# MOTOR register map
Registers are 32-bit, access not given, no defined reset value unless marked. A register's access mark holds for its fields unless they carry their own. Addresses are absolute; registers are grouped by the start of their names; [hi:lo] are bit positions; {n}, {i} and the like mark numbered series.

## GLOBAL
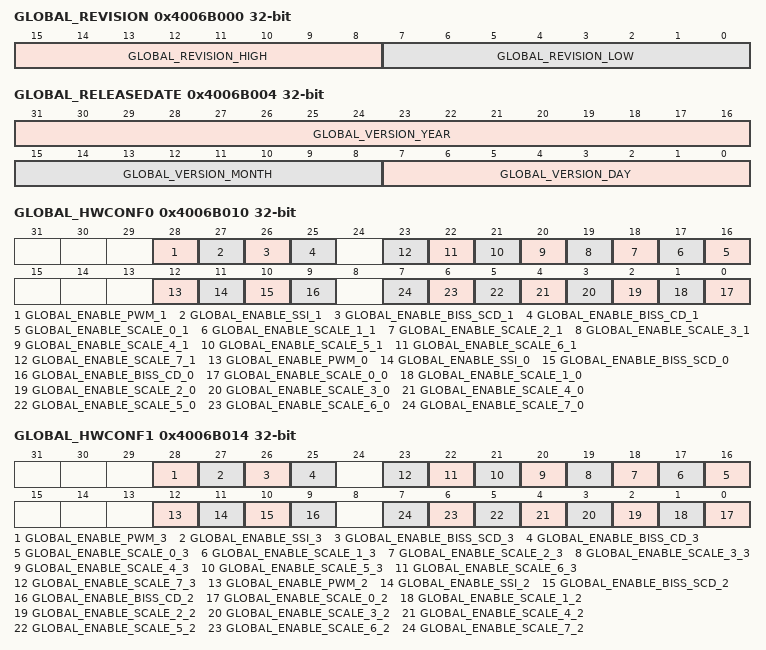
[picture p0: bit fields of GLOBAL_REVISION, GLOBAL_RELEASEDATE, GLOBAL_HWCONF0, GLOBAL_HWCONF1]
0x4006B000 GLOBAL_REVISION ro
  [15:8] GLOBAL_REVISION_HIGH, [7:0] GLOBAL_REVISION_LOW
0x4006B004 GLOBAL_RELEASEDATE ro
  [31:16] GLOBAL_VERSION_YEAR, [15:8] GLOBAL_VERSION_MONTH, [7:0] GLOBAL_VERSION_DAY
0x4006B010 GLOBAL_HWCONF0 ro
  [28] GLOBAL_ENABLE_PWM_1, [27] GLOBAL_ENABLE_SSI_1, [26] GLOBAL_ENABLE_BISS_SCD_1, [25] GLOBAL_ENABLE_BISS_CD_1, [n+16] GLOBAL_ENABLE_SCALE_{n}_1 (n=0..7), [12] GLOBAL_ENABLE_PWM_0, [11] GLOBAL_ENABLE_SSI_0, [10] GLOBAL_ENABLE_BISS_SCD_0, [9] GLOBAL_ENABLE_BISS_CD_0, [n] GLOBAL_ENABLE_SCALE_{n}_0 (n=0..7)
0x4006B014 GLOBAL_HWCONF1 ro
  [28] GLOBAL_ENABLE_PWM_3, [27] GLOBAL_ENABLE_SSI_3, [26] GLOBAL_ENABLE_BISS_SCD_3, [25] GLOBAL_ENABLE_BISS_CD_3, [n+16] GLOBAL_ENABLE_SCALE_{n}_3 (n=0..7), [12] GLOBAL_ENABLE_PWM_2, [11] GLOBAL_ENABLE_SSI_2, [10] GLOBAL_ENABLE_BISS_SCD_2, [9] GLOBAL_ENABLE_BISS_CD_2, [n] GLOBAL_ENABLE_SCALE_{n}_2 (n=0..7)
0x4006B018 GLOBAL_HWCONF2 ro
0x4006B01C GLOBAL_HWCONF3 ro
0x4006B080 GLOBAL_SETTINGS
  [1:0] GLOBAL_CLOCK_SEL

## ROUTING
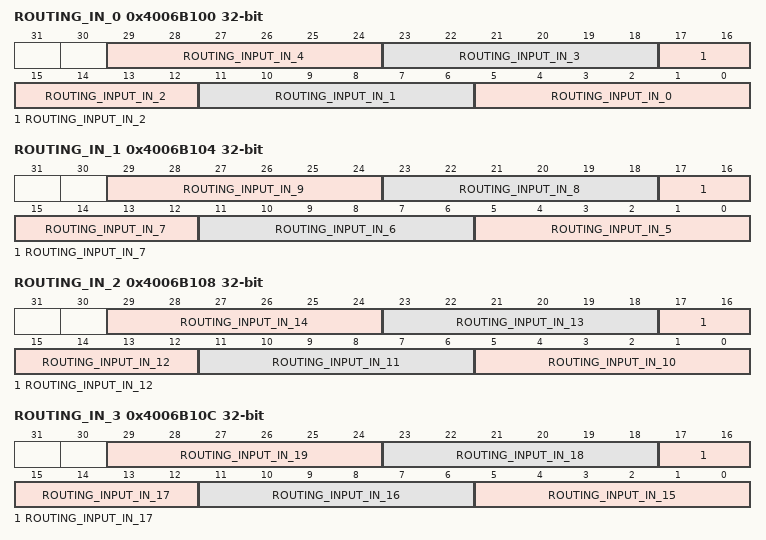
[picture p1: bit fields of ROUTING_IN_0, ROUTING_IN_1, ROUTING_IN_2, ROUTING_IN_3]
0x4006B100 ROUTING_IN_0
  [6n+5:6n] ROUTING_INPUT_IN_{n} (n=0..4)
0x4006B104 ROUTING_IN_1
  [6n-25:6n-30] ROUTING_INPUT_IN_{n} (n=5..9)
0x4006B108 ROUTING_IN_2
  [6n-55:6n-60] ROUTING_INPUT_IN_{n} (n=10..14)
0x4006B10C ROUTING_IN_3
  [6n-85:6n-90] ROUTING_INPUT_IN_{n} (n=15..19)
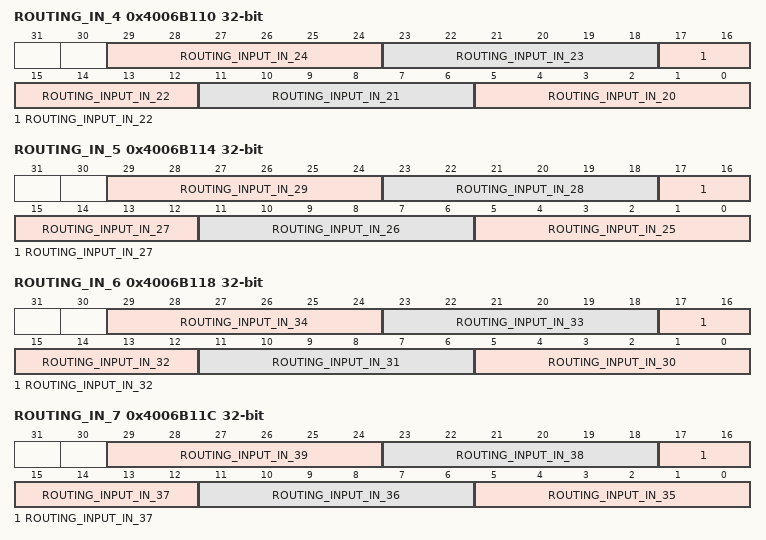
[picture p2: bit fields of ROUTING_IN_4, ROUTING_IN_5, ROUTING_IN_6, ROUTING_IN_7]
0x4006B110 ROUTING_IN_4
  [6n-115:6n-120] ROUTING_INPUT_IN_{n} (n=20..24)
0x4006B114 ROUTING_IN_5
  [6n-145:6n-150] ROUTING_INPUT_IN_{n} (n=25..29)
0x4006B118 ROUTING_IN_6
  [6n-175:6n-180] ROUTING_INPUT_IN_{n} (n=30..34)
0x4006B11C ROUTING_IN_7
  [6n-205:6n-210] ROUTING_INPUT_IN_{n} (n=35..39)
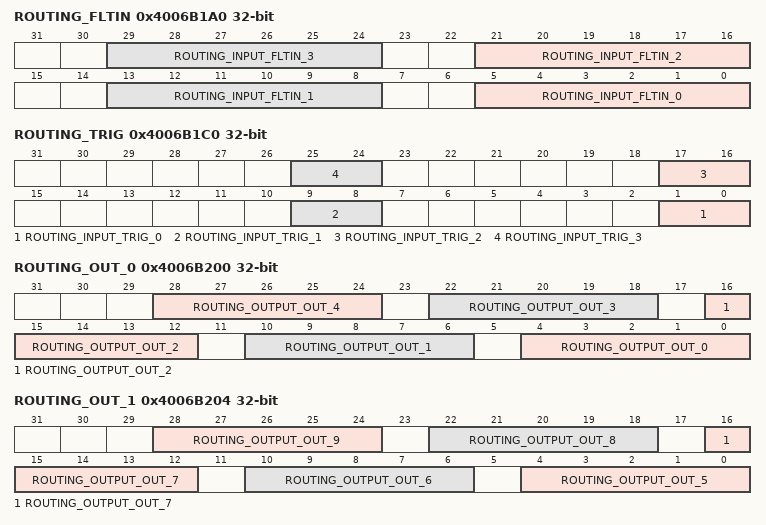
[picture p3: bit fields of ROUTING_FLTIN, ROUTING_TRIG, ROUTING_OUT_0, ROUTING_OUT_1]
0x4006B1A0 ROUTING_FLTIN
  [8n+5:8n] ROUTING_INPUT_FLTIN_{n} (n=0..3)
0x4006B1C0 ROUTING_TRIG
  [8n+1:8n] ROUTING_INPUT_TRIG_{n} (n=0..3)
0x4006B200 ROUTING_OUT_0
  [6n+4:6n] ROUTING_OUTPUT_OUT_{n} (n=0..4)
0x4006B204 ROUTING_OUT_1
  [6n-26:6n-30] ROUTING_OUTPUT_OUT_{n} (n=5..9)
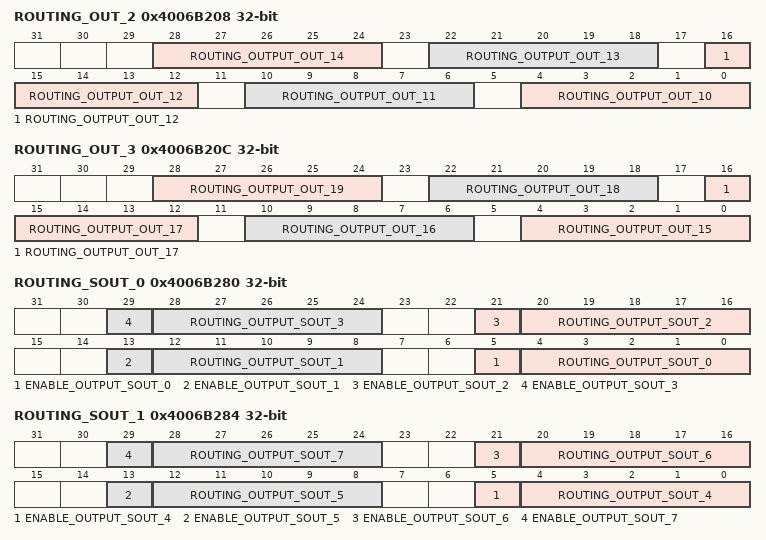
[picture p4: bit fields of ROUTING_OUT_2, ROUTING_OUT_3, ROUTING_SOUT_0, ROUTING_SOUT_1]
0x4006B208 ROUTING_OUT_2
  [6n-56:6n-60] ROUTING_OUTPUT_OUT_{n} (n=10..14)
0x4006B20C ROUTING_OUT_3
  [6n-86:6n-90] ROUTING_OUTPUT_OUT_{n} (n=15..19)
0x4006B280 ROUTING_SOUT_0
  [8n+5] ENABLE_OUTPUT_SOUT_{n} (n=0..3), [8n+4:8n] ROUTING_OUTPUT_SOUT_{n} (n=0..3)
0x4006B284 ROUTING_SOUT_1
  [8n-27] ENABLE_OUTPUT_SOUT_{n} (n=4..7), [8n-28:8n-32] ROUTING_OUTPUT_SOUT_{n} (n=4..7)
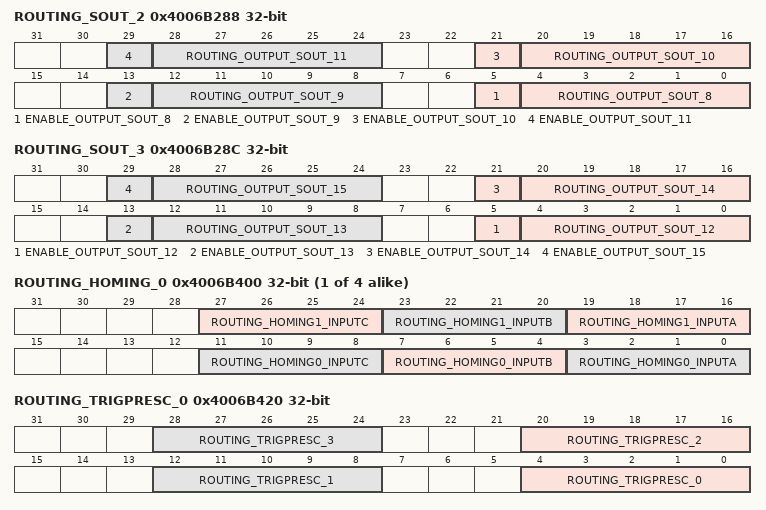
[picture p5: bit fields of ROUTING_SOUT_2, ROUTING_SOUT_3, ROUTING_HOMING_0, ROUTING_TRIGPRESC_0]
0x4006B288 ROUTING_SOUT_2
  [8n-59] ENABLE_OUTPUT_SOUT_{n} (n=8..11), [8n-60:8n-64] ROUTING_OUTPUT_SOUT_{n} (n=8..11)
0x4006B28C ROUTING_SOUT_3
  [8n-91] ENABLE_OUTPUT_SOUT_{n} (n=12..15), [8n-92:8n-96] ROUTING_OUTPUT_SOUT_{n} (n=12..15)
{0x4006B400+4i} ROUTING_HOMING_{i} (i=0..3)
  [27:24] ROUTING_HOMING{2i+1}_INPUTC, [23:20] ROUTING_HOMING{2i+1}_INPUTB, [19:16] ROUTING_HOMING{2i+1}_INPUTA, [11:8] ROUTING_HOMING{2i}_INPUTC, [7:4] ROUTING_HOMING{2i}_INPUTB, [3:0] ROUTING_HOMING{2i}_INPUTA
0x4006B420 ROUTING_TRIGPRESC_0
  [8n+4:8n] ROUTING_TRIGPRESC_{n} (n=0..3)
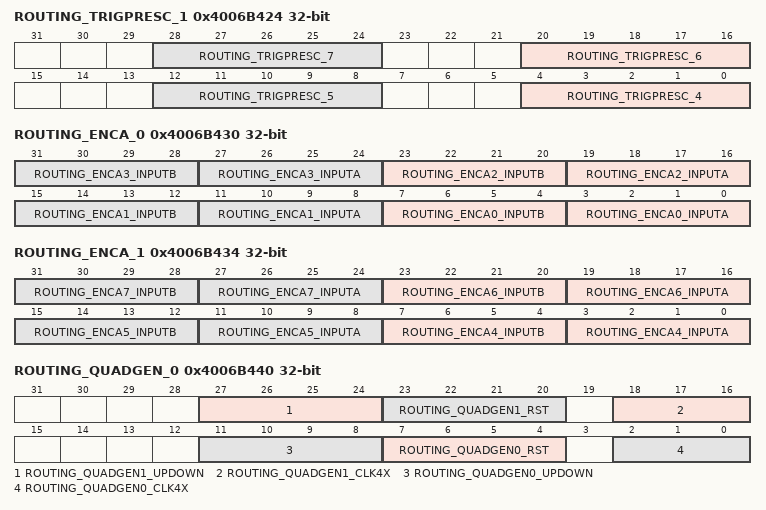
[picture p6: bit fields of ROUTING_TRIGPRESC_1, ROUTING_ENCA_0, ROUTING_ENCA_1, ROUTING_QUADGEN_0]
0x4006B424 ROUTING_TRIGPRESC_1
  [8n-28:8n-32] ROUTING_TRIGPRESC_{n} (n=4..7)
0x4006B430 ROUTING_ENCA_0
  [8n+7:8n+4] ROUTING_ENCA{n}_INPUTB (n=0..3), [8n+3:8n] ROUTING_ENCA{n}_INPUTA (n=0..3)
0x4006B434 ROUTING_ENCA_1
  [8n-25:8n-28] ROUTING_ENCA{n}_INPUTB (n=4..7), [8n-29:8n-32] ROUTING_ENCA{n}_INPUTA (n=4..7)
0x4006B440 ROUTING_QUADGEN_0
  [27:24] ROUTING_QUADGEN1_UPDOWN, [23:20] ROUTING_QUADGEN1_RST, [18:16] ROUTING_QUADGEN1_CLK4X, [11:8] ROUTING_QUADGEN0_UPDOWN, [7:4] ROUTING_QUADGEN0_RST, [2:0] ROUTING_QUADGEN0_CLK4X
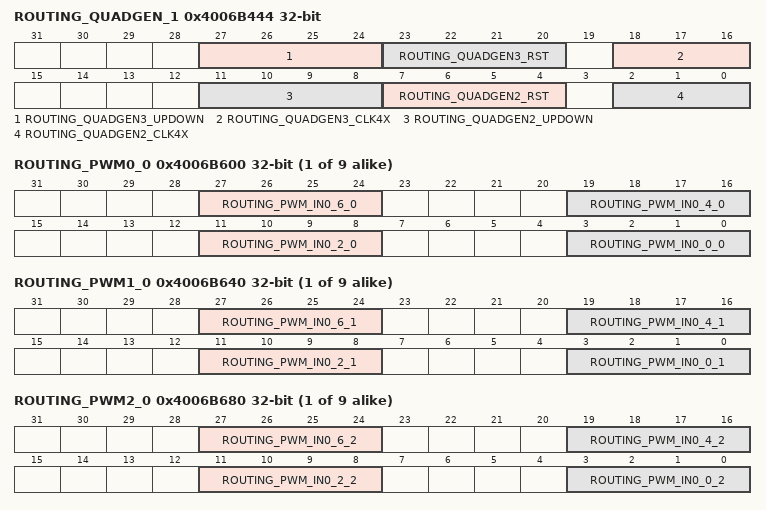
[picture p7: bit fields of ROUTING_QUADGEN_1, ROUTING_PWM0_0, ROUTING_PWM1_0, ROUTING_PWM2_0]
0x4006B444 ROUTING_QUADGEN_1
  [27:24] ROUTING_QUADGEN3_UPDOWN, [23:20] ROUTING_QUADGEN3_RST, [18:16] ROUTING_QUADGEN3_CLK4X, [11:8] ROUTING_QUADGEN2_UPDOWN, [7:4] ROUTING_QUADGEN2_RST, [2:0] ROUTING_QUADGEN2_CLK4X
{0x4006B600+4i} ROUTING_PWM0_{i} (i=0..8)
  [27:24] ROUTING_PWM_IN{i}_6_0, [19:16] ROUTING_PWM_IN{i}_4_0, [11:8] ROUTING_PWM_IN{i}_2_0, [3:0] ROUTING_PWM_IN{i}_0_0
{0x4006B640+4i} ROUTING_PWM1_{i} (i=0..8)
  [27:24] ROUTING_PWM_IN{i}_6_1, [19:16] ROUTING_PWM_IN{i}_4_1, [11:8] ROUTING_PWM_IN{i}_2_1, [3:0] ROUTING_PWM_IN{i}_0_1
{0x4006B680+4i} ROUTING_PWM2_{i} (i=0..8)
  [27:24] ROUTING_PWM_IN{i}_6_2, [19:16] ROUTING_PWM_IN{i}_4_2, [11:8] ROUTING_PWM_IN{i}_2_2, [3:0] ROUTING_PWM_IN{i}_0_2
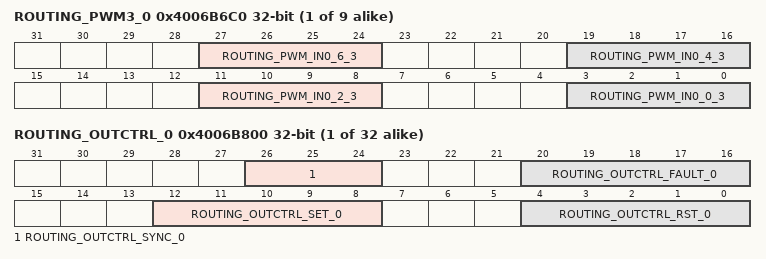
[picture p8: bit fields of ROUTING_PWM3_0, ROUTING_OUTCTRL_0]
{0x4006B6C0+4i} ROUTING_PWM3_{i} (i=0..8)
  [27:24] ROUTING_PWM_IN{i}_6_3, [19:16] ROUTING_PWM_IN{i}_4_3, [11:8] ROUTING_PWM_IN{i}_2_3, [3:0] ROUTING_PWM_IN{i}_0_3
{0x4006B800+4i} ROUTING_OUTCTRL_{i} (i=0..31)
  [26:24] ROUTING_OUTCTRL_SYNC_{i}, [20:16] ROUTING_OUTCTRL_FAULT_{i}, [12:8] ROUTING_OUTCTRL_SET_{i}, [4:0] ROUTING_OUTCTRL_RST_{i}

## DMA
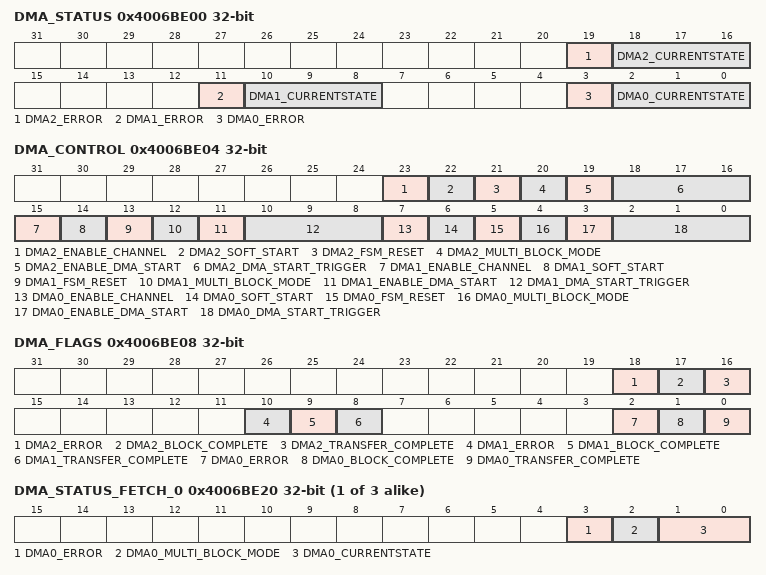
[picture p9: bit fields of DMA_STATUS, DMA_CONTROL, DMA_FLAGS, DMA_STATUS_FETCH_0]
0x4006BE00 DMA_STATUS ro
  [19] DMA2_ERROR, [18:16] DMA2_CURRENTSTATE, [11] DMA1_ERROR, [10:8] DMA1_CURRENTSTATE, [3] DMA0_ERROR, [2:0] DMA0_CURRENTSTATE
0x4006BE04 DMA_CONTROL
  [23] DMA2_ENABLE_CHANNEL, [22] DMA2_SOFT_START, [21] DMA2_FSM_RESET, [20] DMA2_MULTI_BLOCK_MODE, [19] DMA2_ENABLE_DMA_START, [18:16] DMA2_DMA_START_TRIGGER, [15] DMA1_ENABLE_CHANNEL, [14] DMA1_SOFT_START, [13] DMA1_FSM_RESET, [12] DMA1_MULTI_BLOCK_MODE, [11] DMA1_ENABLE_DMA_START, [10:8] DMA1_DMA_START_TRIGGER, [7] DMA0_ENABLE_CHANNEL, [6] DMA0_SOFT_START, [5] DMA0_FSM_RESET, [4] DMA0_MULTI_BLOCK_MODE, [3] DMA0_ENABLE_DMA_START, [2:0] DMA0_DMA_START_TRIGGER
0x4006BE08 DMA_FLAGS
  [18] DMA2_ERROR, [17] DMA2_BLOCK_COMPLETE, [16] DMA2_TRANSFER_COMPLETE, [10] DMA1_ERROR, [9] DMA1_BLOCK_COMPLETE, [8] DMA1_TRANSFER_COMPLETE, [2] DMA0_ERROR, [1] DMA0_BLOCK_COMPLETE, [0] DMA0_TRANSFER_COMPLETE
{0x4006BE20+0x20*i} DMA_STATUS_FETCH_{i} ro (i=0..2)
  [3] DMA{i}_ERROR, [2] DMA{i}_MULTI_BLOCK_MODE, [1:0] DMA{i}_CURRENTSTATE
{0x4006BE28+0x20*i} DMA_LAST_BLOCK_{i} (i=0..2)
